AUTOSAR XML (schema 00049)
package /SwComponentTypes
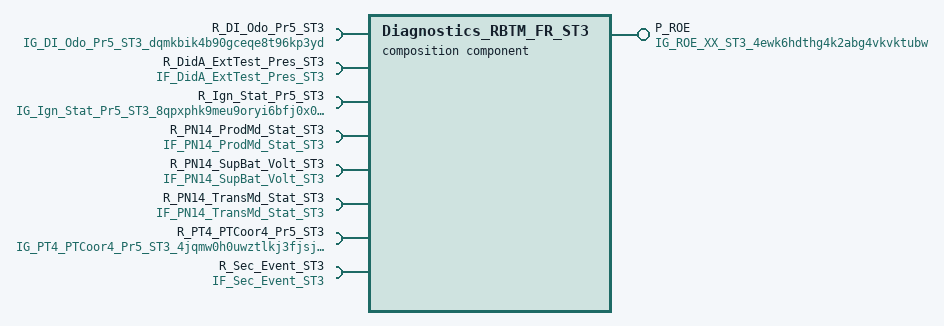
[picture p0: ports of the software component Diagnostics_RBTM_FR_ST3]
  composition sw component type Diagnostics_RBTM_FR_ST3
    provide port P_ROE: nonqueued-sender-com-spec{data-element=ROE_XX_ST3, init-value=constant-reference=XDIS_95xfwhvar8lzg9cdzofn4oooa}, provided-interface=IG_ROE_XX_ST3_4ewk6hdthg4k2abg4vkvktubw  # Ereignis-Antwort (degraded) / Response on Event (degraded)
    8 x require port:
      R_DI_Odo_Pr5_ST3: nonqueued-receiver-com-spec{data-element=DI_Odo_Pr5_ST3, reception-props=timeout=0, end-to-end-transformation-com-spec-props=disable-end-to-end-check=true, init-value=constant-reference=XDIS_8ty18e89uj9dq1u10d39n5ao8}, required-interface=IG_DI_Odo_Pr5_ST3_dqmkbik4b90gceqe8t96kp3yd  # DriverInformation Odometer (degraded)
      R_DidA_ExtTest_Pres_ST3: nonqueued-receiver-com-spec{data-element=DidA_ExtTest_Pres_ST3, reception-props=timeout=0, init-value=constant-reference=XDIS_f4mtuwvd3r353o80f6rps7w7}, required-interface=IF_DidA_ExtTest_Pres_ST3  # DidA Externer Tester erkannt / DidA external tester present
      R_Ign_Stat_Pr5_ST3: nonqueued-receiver-com-spec{data-element=Ign_Stat_Pr5_ST3, reception-props=timeout=0, end-to-end-transformation-com-spec-props=disable-end-to-end-check=true, init-value=constant-reference=XDIS_27u3muzqwjdvnos2w0sy90oxa}, required-interface=IG_Ign_Stat_Pr5_ST3_8qpxphk9meu9oryi6bfj0x04b  # Zuendungsstatus (degraded) / Ignition state (degraded)
      R_PN14_ProdMd_Stat_ST3: nonqueued-receiver-com-spec{data-element=PN14_ProdMd_Stat_ST3, reception-props=timeout=0, init-value=constant-reference=XDIS_4um78o9kgep1cp3dhn51ycc2o}, required-interface=IF_PN14_ProdMd_Stat_ST3  # Status des Bordnetz Produktionsmodus / Powernet production mode state
      R_PN14_SupBat_Volt_ST3: nonqueued-receiver-com-spec{data-element=PN14_SupBat_Volt_ST3, reception-props=timeout=0, init-value=constant-reference=XDIS_9jzhpgyeg4j2n16k3jmfeesjo}, required-interface=IF_PN14_SupBat_Volt_ST3  # Versorgungsbatterie Istspannung / Supply battery voltage
      R_PN14_TransMd_Stat_ST3: nonqueued-receiver-com-spec{data-element=PN14_TransMd_Stat_ST3, reception-props=timeout=0, init-value=constant-reference=XDIS_18rb2bxx4r5d75figzrcw50gp}, required-interface=IF_PN14_TransMd_Stat_ST3  # Bordnetz Status Transportmodus / Powernet transport mode status
      R_PT4_PTCoor4_Pr5_ST3: nonqueued-receiver-com-spec{data-element=PT4_PTCoor4_Pr5_ST3, reception-props=timeout=0, end-to-end-transformation-com-spec-props=disable-end-to-end-check=true, init-value=constant-reference=XDIS_dclbmhxy3xotv8ng3m00etq21}, required-interface=IG_PT4_PTCoor4_Pr5_ST3_4jqmw0h0uwztlkj3fjsj9fpfe  # PT4_PTCoor4_Pr5_ST3 (degraded)
      R_Sec_Event_ST3: nonqueued-receiver-com-spec{data-element=Data, reception-props=timeout=0, init-value=constant-reference=XDIS_6146w3b2vgdunnu49c413rpbf}, required-interface=IF_Sec_Event_ST3  # Security-Ereignis / Security event
